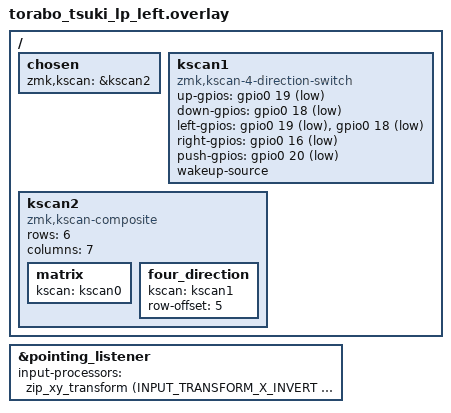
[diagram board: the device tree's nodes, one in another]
#include "torabo_tsuki_lp.dtsi"
#include <input/processors.dtsi>
#include <dt-bindings/zmk/input_transform.h>

&pointing_listener {
    input-processors = <&zip_xy_transform (INPUT_TRANSFORM_X_INVERT | INPUT_TRANSFORM_Y_INVERT)>;
};

/ {
    chosen {
        zmk,kscan = &kscan2;
    };

    /* 4方向スイッチの kscan 定義 */
    kscan1: kscan1 {
        compatible = "zmk,kscan-4-direction-switch";

        up-gpios = <&gpio0 19 (GPIO_ACTIVE_LOW | GPIO_PULL_UP)>;
        down-gpios = <&gpio0 18 (GPIO_ACTIVE_LOW | GPIO_PULL_UP)>;
        left-gpios = <&gpio0 19 (GPIO_ACTIVE_LOW | GPIO_PULL_UP)>,
                     <&gpio0 18 (GPIO_ACTIVE_LOW | GPIO_PULL_UP)>;
        right-gpios = <&gpio0 16 (GPIO_ACTIVE_LOW | GPIO_PULL_UP)>;
        push-gpios = <&gpio0 20 (GPIO_ACTIVE_LOW | GPIO_PULL_UP)>;

        wakeup-source;
    };

    /* キーボードの通常マトリクス + 4方向スイッチを合成する */
    kscan2: kscan2 {
        compatible = "zmk,kscan-composite";
        rows = <6>;
        columns = <7>;

        matrix {
            kscan = <&kscan0>;
        };

        /* 4方向スイッチを row 5 に追加する */
        four_direction {
            kscan = <&kscan1>;
            row-offset = <5>;
        };
    };
};
